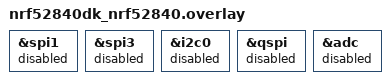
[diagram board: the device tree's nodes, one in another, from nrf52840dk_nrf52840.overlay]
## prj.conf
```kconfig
CONFIG_NRFX_SPIM3=y 
```

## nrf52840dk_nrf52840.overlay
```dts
// To get started, press Ctrl+Space to bring up the completion menu and view the available nodes.

// You can also use the buttons in the sidebar to perform actions on nodes.
// Actions currently available include:

// * Enabling / disabling the node
// * Adding the bus to a bus
// * Removing the node
// * Connecting ADC channels

// For more help, browse the DeviceTree documentation at https://docs.zephyrproject.org/latest/guides/dts/index.html
// You can also visit the nRF DeviceTree extension documentation at https://nrfconnect.github.io/vscode-nrf-connect/devicetree/nrfdevicetree.html

&spi1 {
	status = "disabled";
};

&spi3 {
	status = "disabled";
};

&i2c0 {
	status = "disabled";
};

&qspi {
	status = "disabled";
};

&adc {
	status = "disabled";
};
```

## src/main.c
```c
/*
 * Copyright (c) 2012-2014 Wind River Systems, Inc.
 *
 * SPDX-License-Identifier: Apache-2.0
 */

#include <stdio.h>
#include "lcd.h"
#include "lcd_init.h"

int main(void)
{
	LCD_Init();
	LCD_Fill(0,0,LCD_W,LCD_H,BLUE);

	LCD_ShowString(20, 50, "Hello World!", RED, WHITE, 32, 0);

	while(1)
	{
		
		for(uint16_t x = 0; x < 240; x++)
		{
			for(uint16_t y = 180; y < 200; y++)
			{
				LCD_DrawPoint(x, y, GREEN);
			}
		}

		for(uint16_t x = 0; x < 240; x++)
		{
			for(uint16_t y = 180; y < 200; y++)
			{
				LCD_DrawPoint(x, y, BLUE);
			}
		}
	}
	
	return 0;
}
```

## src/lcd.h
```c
#ifndef __LCD_H
#define __LCD_H

#include "lcd.h"
#include "lcd_init.h"

void LCD_Fill(uint16_t xsta, uint16_t ysta, uint16_t xend, uint16_t yend, uint16_t color);  // fill a color
void LCD_DrawPoint(uint16_t x, uint16_t y, uint16_t color);                                 // draw a point
void LCD_DrawLine(uint16_t x1, uint16_t y1, uint16_t x2, uint16_t y2, uint16_t color);      // draw a line
void LCD_DrawRectangle(uint16_t x1, uint16_t y1, uint16_t x2, uint16_t y2, uint16_t color); // draw a rectangle
void Draw_Circle(uint16_t x0, uint16_t y0, uint8_t r, uint16_t color);                      // draw a circle

void LCD_ShowChinese(uint16_t x, uint16_t y, uint8_t *s, uint16_t fc, uint16_t bc, uint8_t sizey, uint8_t mode);      // display a Chinese character
void LCD_ShowChinese12x12(uint16_t x, uint16_t y, uint8_t *s, uint16_t fc, uint16_t bc, uint8_t sizey, uint8_t mode); // display a 12x12 Chinese character
void LCD_ShowChinese16x16(uint16_t x, uint16_t y, uint8_t *s, uint16_t fc, uint16_t bc, uint8_t sizey, uint8_t mode); // display a 16x16 Chinese character
void LCD_ShowChinese24x24(uint16_t x, uint16_t y, uint8_t *s, uint16_t fc, uint16_t bc, uint8_t sizey, uint8_t mode); // display a 24x24 Chinese character
void LCD_ShowChinese32x32(uint16_t x, uint16_t y, uint8_t *s, uint16_t fc, uint16_t bc, uint8_t sizey, uint8_t mode); // display a 32x32 Chinese character

void LCD_ShowChar(uint16_t x, uint16_t y, uint8_t num, uint16_t fc, uint16_t bc, uint8_t sizey, uint8_t mode);        // display a character
void LCD_ShowString(uint16_t x, uint16_t y, const uint8_t *p, uint16_t fc, uint16_t bc, uint8_t sizey, uint8_t mode); // display a string
uint32_t mypow(uint8_t m, uint8_t n);                                                                                 // m^n
void LCD_ShowIntNum(uint16_t x, uint16_t y, uint16_t num, uint8_t len, uint16_t fc, uint16_t bc, uint8_t sizey);      // display an integer
void LCD_ShowFloatNum1(uint16_t x, uint16_t y, float num, uint8_t len, uint16_t fc, uint16_t bc, uint8_t sizey);      // display a float number

void LCD_ShowPicture(uint16_t x, uint16_t y, uint16_t length, uint16_t width, const uint8_t pic[]); // display a picture

// color
#define WHITE 0xFFFF
#define BLACK 0x0000
#define BLUE 0x001F
#define BRED 0XF81F
#define GRED 0XFFE0
#define GBLUE 0X07FF
#define RED 0xF800
#define MAGENTA 0xF81F
#define GREEN 0x07E0
#define CYAN 0x7FFF
#define YELLOW 0xFFE0
#define BROWN 0XBC40      // brown
#define BRRED 0XFC07      // light brown
#define GRAY 0X8430       // gray
#define DARKBLUE 0X01CF   // dark blue
#define LIGHTBLUE 0X7D7C  // light blue
#define GRAYBLUE 0X5458   // gray blue
#define LIGHTGREEN 0X841F // light green
#define LGRAY 0XC618      // light gray (used to display the button)
#define LGRAYBLUE 0XA651  // light gray blue (used to display the button)
#define LBBLUE 0X2B12     // light brown blue (used to display the button)

#endif
```

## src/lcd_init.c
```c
#include "lcd_init.h"
#include <zephyr/kernel.h>
#include "nrfx_spim.h"
#include "hal/nrf_gpio.h"
#include <hal/nrf_spim.h>

static nrfx_spim_t spi_instance = NRFX_SPIM_INSTANCE(3);

int SPI_init(void)
{
    nrfx_spim_config_t spi_config = NRFX_SPIM_DEFAULT_CONFIG(LCD_SCLK_PIN, LCD_MOSI_PIN, NRF_SPIM_PIN_NOT_CONNECTED, LCD_CS_PIN);
    spi_config.frequency = NRF_SPIM_FREQ_4M;

    nrfx_spim_init(&spi_instance, &spi_config, NULL, NULL);
}

void SPI_write(uint8_t *data, uint16_t len)
{
    nrfx_spim_xfer_desc_t spi_tx_buff = NRFX_SPIM_XFER_TX(data, len);
    nrfx_spim_xfer(&spi_instance, &spi_tx_buff, 0);
}

void SPI_read(uint8_t *data, uint16_t len)
{
    nrfx_spim_xfer_desc_t spi_rx_buff = NRFX_SPIM_XFER_RX(data, len);
    nrfx_spim_xfer(&spi_instance, &spi_rx_buff, 0);
}


void LCD_GPIO_Init(void)
{
    SPI_init();
    
    nrf_gpio_cfg_output(LCD_RESET_PIN);
    nrf_gpio_cfg_output(LCD_DC_PIN);
    nrf_gpio_cfg_output(LCD_BLK_PIN);

    nrf_gpio_pin_set(LCD_RESET_PIN);
    nrf_gpio_pin_set(LCD_DC_PIN);
    nrf_gpio_pin_set(LCD_BLK_PIN);
}

void LCD_Writ_Bus(uint8_t dat)
{
    SPI_write(&dat, 1);
}

void LCD_WR_DATA8(uint8_t dat)
{
    LCD_Writ_Bus(dat);
}

void LCD_WR_DATA(uint16_t dat)
{
    uint8_t buffer[2] = {dat >> 8, dat};
    SPI_write(buffer, 2);
}

void LCD_WR_REG(uint8_t dat)
{
    LCD_DC_Clr(); // Write command
    LCD_Writ_Bus(dat);
    LCD_DC_Set(); // Write data
}

void LCD_Address_Set(uint16_t x1, uint16_t y1, uint16_t x2, uint16_t y2)
{
    if (USE_HORIZONTAL == 0)
    {
        LCD_WR_REG(0x2a); // Column address set
        LCD_WR_DATA(x1);
        LCD_WR_DATA(x2);
        LCD_WR_REG(0x2b); // Row address set
        LCD_WR_DATA(y1 + 20);
        LCD_WR_DATA(y2 + 20);
        LCD_WR_REG(0x2c); // RAM write
    }
    else if (USE_HORIZONTAL == 1)
    {
        LCD_WR_REG(0x2a); // Column address set
        LCD_WR_DATA(x1);
        LCD_WR_DATA(x2);
        LCD_WR_REG(0x2b); // Row address set
        LCD_WR_DATA(y1 + 20);
        LCD_WR_DATA(y2 + 20);
        LCD_WR_REG(0x2c); // RAM write
    }
    else if (USE_HORIZONTAL == 2)
    {
        LCD_WR_REG(0x2a);
        LCD_WR_DATA(x1 + 20);
        LCD_WR_DATA(x2 + 20);
        LCD_WR_REG(0x2b);
        LCD_WR_DATA(y1);
        LCD_WR_DATA(y2);
        LCD_WR_REG(0x2c);
    }
    else
    {
        LCD_WR_REG(0x2a);
        LCD_WR_DATA(x1 + 20);
        LCD_WR_DATA(x2 + 20);
        LCD_WR_REG(0x2b);
        LCD_WR_DATA(y1);
        LCD_WR_DATA(y2);
        LCD_WR_REG(0x2c);
    }
}

void LCD_Init(void)
{
    LCD_GPIO_Init(); // Init GPIO
    k_msleep(100);
    LCD_RES_Clr();  // Reset
    k_msleep(100);
    LCD_RES_Set();
    k_msleep(100);

    LCD_BLK_Set(); // Open backlight
    k_msleep(100);

    //************* Start Initial Sequence **********//
    LCD_WR_REG(0x11); // Sleep out
    k_msleep(120);    // Delay 120ms
    //************* Start Initial Sequence **********//
    LCD_WR_REG(0x36);   // Memory Data Access Control
    if (USE_HORIZONTAL == 0)
        LCD_WR_DATA8(0x00); 
    else if (USE_HORIZONTAL == 1)
        LCD_WR_DATA8(0xC0);
    else if (USE_HORIZONTAL == 2)
        LCD_WR_DATA8(0x70);
    else
        LCD_WR_DATA8(0xA0);

    LCD_WR_REG(0x3A);   // Interface Pixel Format
    LCD_WR_DATA8(0x05);

    LCD_WR_REG(0xB2);   // Porch Setting
    LCD_WR_DATA8(0x0C);
    LCD_WR_DATA8(0x0C);
    LCD_WR_DATA8(0x00);
    LCD_WR_DATA8(0x33);
    LCD_WR_DATA8(0x33);

    LCD_WR_REG(0xB7);   // Gate Control
    LCD_WR_DATA8(0x35);

    LCD_WR_REG(0xBB);   // Vcom Setting
    LCD_WR_DATA8(0x32); // Vcom=1.35V

    LCD_WR_REG(0xC2);   // vdvs
    LCD_WR_DATA8(0x01);

    LCD_WR_REG(0xC3);   // Vrhs
    LCD_WR_DATA8(0x15); // GVDD=4.8V  Coler Deep

    LCD_WR_REG(0xC4);   // Vdvs
    LCD_WR_DATA8(0x20); // VDV, 0x20:0v

    LCD_WR_REG(0xC6);   // Frctrl2
    LCD_WR_DATA8(0x0F); // 0x0F:60Hz

    LCD_WR_REG(0xD0);   // Power Setting
    LCD_WR_DATA8(0xA4);
    LCD_WR_DATA8(0xA1);

    LCD_WR_REG(0xE0);   // Positive Voltage Gamma Control
    LCD_WR_DATA8(0xD0);
    LCD_WR_DATA8(0x08);
    LCD_WR_DATA8(0x0E);
    LCD_WR_DATA8(0x09);
    LCD_WR_DATA8(0x09);
    LCD_WR_DATA8(0x05);
    LCD_WR_DATA8(0x31);
    LCD_WR_DATA8(0x33);
    LCD_WR_DATA8(0x48);
    LCD_WR_DATA8(0x17);
    LCD_WR_DATA8(0x14);
    LCD_WR_DATA8(0x15);
    LCD_WR_DATA8(0x31);
    LCD_WR_DATA8(0x34);

    LCD_WR_REG(0xE1);   // Negative Voltage Gamma Control
    LCD_WR_DATA8(0xD0);
    LCD_WR_DATA8(0x08);
    LCD_WR_DATA8(0x0E);
    LCD_WR_DATA8(0x09);
    LCD_WR_DATA8(0x09);
    LCD_WR_DATA8(0x15);
    LCD_WR_DATA8(0x31);
    LCD_WR_DATA8(0x33);
    LCD_WR_DATA8(0x48);
    LCD_WR_DATA8(0x17);
    LCD_WR_DATA8(0x14);
    LCD_WR_DATA8(0x15);
    LCD_WR_DATA8(0x31);
    LCD_WR_DATA8(0x34);

    LCD_WR_REG(0x21);   // Display Inversion On

    LCD_WR_REG(0x29);   // Display On
}
```
